# TC80_VXX register map
Vendor: Geneal MCU Ltd.; Series: ARMCM0; File version: 1.2
CPU: CM0 r0p0, little endian, no MPU, no FPU, 2 interrupt priority bits
Registers are 32-bit, read-write, reset 0x0 unless marked. A register's access mark holds for its fields unless they carry their own. Offsets are from the block's base; [hi:lo] are bit positions; lines under a group give offsets from that group; {n}, {i} and the like mark numbered series.

## ADC — Analog-to-digital converter
Base 0x49007000
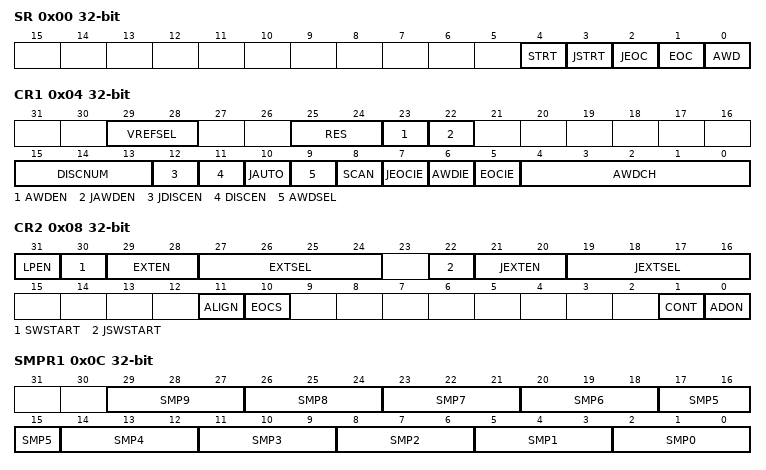
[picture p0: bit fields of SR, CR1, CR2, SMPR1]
0x00 SR (reset mask 0xF) — ADC status register
  [4] STRT — Regular channel start conversion flag
    0=No_STRT (Regular channal conversion not start); 1=STRT_Occured (Regular channal conversion start)
  [3] JSTRT — Injected channel start conversion flag
    0=No_JSTRT (Injected channal conversion not start); 1=JSTRT_Occured (Injected channal conversion start)
  [2] JEOC — Injected channel end of conversion flag
    0=No_JEOC (Injected channal conversion not complete); 1=JEOC_Occured (Injected channal conversion complete)
  [1] EOC — End of conversion flag
    0=No_EOC (Channal conversion not complete); 1=EOC_Occured (Channal conversion complete)
  [0] AWD — Analog watchdog flag
    0=No_AWD (Analog watchdog has no occured); 1=AWD_Occured (Analog watchdog has occured)
0x04 CR1 (reset mask 0xCFFFFF) — Control register
  [29:28] VREFSEL — Vref select
    0=1P65 (Select 1.65V internal reference voltage); 1=VDD (Select VDD as reference voltage)
  [25:24] RES — Resolution select
    0=12bit (Select 12 bit resolution); 1=10bit (Select 10 bit resolution); 2=8bit (Select 8 bit resolution); 3=6bit (Select 6 bit resolution)
  [23] AWDEN — Analog watchdog on regular channels enable
    0=Disable (Analog watchdog on regular channels disable); 1=Enable (Analog watchdog on regular channels enable)
  [22] JAWDEN — Analog watchdog on injected channels enable
    0=Disable (Analog watchdog on injected channels disable); 1=Enable (Analog watchdog on injected channels enable)
  [15:13] DISCNUM — Discontinuous mode channel count
  [12] JDISCEN — Discontinuous mode on injected channels
    0=Disable (Discontinuous mode on injected channels disabled); 1=Enable (Discontinuous mode on injected channels enabled)
  [11] DISCEN — Discontinuous mode on regular channels
    0=Disable (Discontinuous mode on regular channels disabled); 1=Enable (Discontinuous mode on regular channels enabled)
  [10] JAUTO — Automatic injected group conversion
    0=Disable (Automatic injected group conversion disabled); 1=Enable (Automatic injected group conversion enabled)
  [9] AWDSEL — Enable the watchdog on a single channel in scan mode
    0=All_Channel; 1=Single_Channel
  [8] SCAN — Scan mode
    0=Disable (Scan mode disabled); 1=Enable (Scan mode enabled)
  [7] JEOCIE — Injected channel end of conversion interrupt enable
    0=Disable (Injected channel end of conversion interrupt disabled); 1=Enable (Injected channel end of conversion interrupt enabled)
  [6] AWDIE — Analog watchdog interrupt enable
    0=Disable (Analog watchdog interrupt disabled); 1=Enable (Analog watchdog interrupt enabled)
  [5] EOCIE — End of conversion interrupt enable
    0=Disable (End of conversion interrupt disabled); 1=Enable (End of conversion interrupt enabled)
  [4:0] AWDCH — Analog watchdog channel select bits
0x08 CR2 — Control register 2
  [31] LPEN — AD converter low power mode enable
    0=Disable (Low power mode disabled); 1=Enable (Low power mode enabled)
  [30] SWSTART — Software trigger for regular group
    0=No_Action; 1=START (Start regular group conversion)
  [29:28] EXTEN — External event select for regular group enable
  [27:24] EXTSEL — External event select for regular group
  [22] JSWSTART — Software trigger for injected group
    0=No_Action; 1=START (Start injected group conversion)
  [21:20] JEXTEN — External event select for injected group enable
  [19:16] JEXTSEL — External event select for injected group
  [11] ALIGN — Data alignment
    0=Right_Align (Rignt align); 1=Left_Align
  [10] EOCS — EOC select
  [1] CONT — Continuous conversion
    0=Singl_Conversion; 1=Continuous_Conversion
  [0] ADON — AD converter on/off
    0=Off (AD converter off); 1=On (AD converter on)
0x0C SMPR1 — Sample time select register 1
  [3n+2:3n] SMP{n} (n=0..9) — Sample time for channel {n}
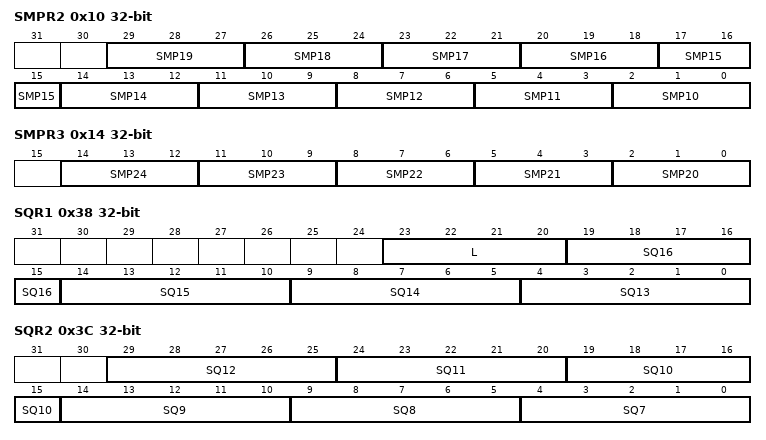
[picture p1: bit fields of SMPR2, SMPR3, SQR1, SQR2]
0x10 SMPR2 — Sample time select register 2
  [3n-28:3n-30] SMP{n} (n=10..19) — Sample time for channel {n}
0x14 SMPR3 — Sample time select register 3
  [3n-58:3n-60] SMP{n} (n=20..24) — Sample time for channel {n}
{0x1C+4i} JOFR{i} (i=1..4) — Offset value register injected channel {i}
  [11:0] JOFFSET — Offset setting data injected channel
0x30 HTR — Analog watchdog high threshold register
  [11:0] HT — Analog watchdog high threshold
0x34 LTR — Analog watchdog low threshold register
  [11:0] LT — Analog watchdog low threshold
0x38 SQR1 — Sequnce control register 1
  [23:20] L — Select sequnce number for conversion
  [5n-61:5n-65] SQ{n} (n=13..16) — Select channel for sequnce {n}
0x3C SQR2 — Sequnce control register 2
  [5n-31:5n-35] SQ{n} (n=7..12) — Select channel for sequnce {n}
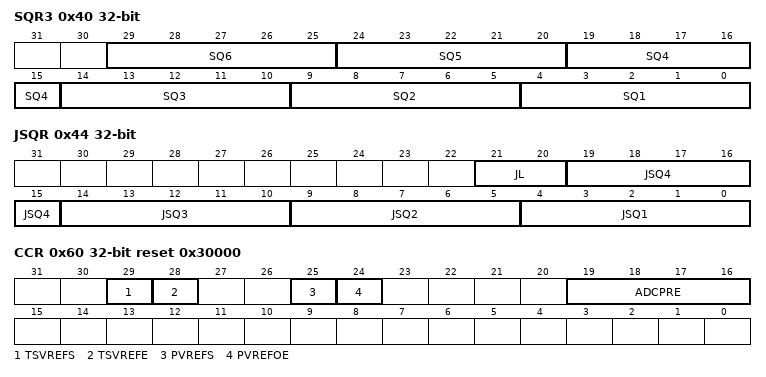
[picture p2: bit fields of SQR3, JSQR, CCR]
0x40 SQR3 — Sequnce control register 1
  [5n-1:5n-5] SQ{n} (n=1..6) — Select channel for sequnce {n}
0x44 JSQR — Injected sequnce control register1
  [21:20] JL — Select injected sequnce number for conversion
  [19:15] JSQ4 — Select channel for sequnce 4
  [14:10] JSQ3 — Select channel for sequnce 3
  [9:5] JSQ2 — Select injected channel for sequnce 2
  [4:0] JSQ1 — Select injected channel for sequnce 1
{0x44+4i} JDR{i} ro (i=1..4) — ADC converted data register for injected sequnce {i}
  [15:0] JDATA — Injected sequnce converted data
0x58 DR ro — ADC converted data register for regular sequnce
  [15:0] DATA — Regular sequnce converted data
0x60 CCR reset 0x30000 — ADC common control register
  [29] TSVREFS — Temp sensor output voltage select
    0=1P8 (Temp sensor output voltage select 1.8V); 1=2P4 (Temp sensor output voltage select 2.4V)
  [28] TSVREFE — Temp sensor enable
    0=Disable (Temp sensor disabled); 1=Enable (Temp sensor enabled)
  [25] PVREFS — Vref output voltage select
    0=1P8 (Vref output voltage select 1.8V); 1=2P4 (Vref output voltage select 2.4V)
  [24] PVREFOE — Vref voltage output enable
    0=Disable (Vref voltage output disabled); 1=Enable (Vref voltage output enabled)
  [19:16] ADCPRE — ADC prescaler
{0x7C+4i} DR{i} ro (i=1..8) — ADC converted data register for sequnce {i}
  [15:0] DATA — Converted data
